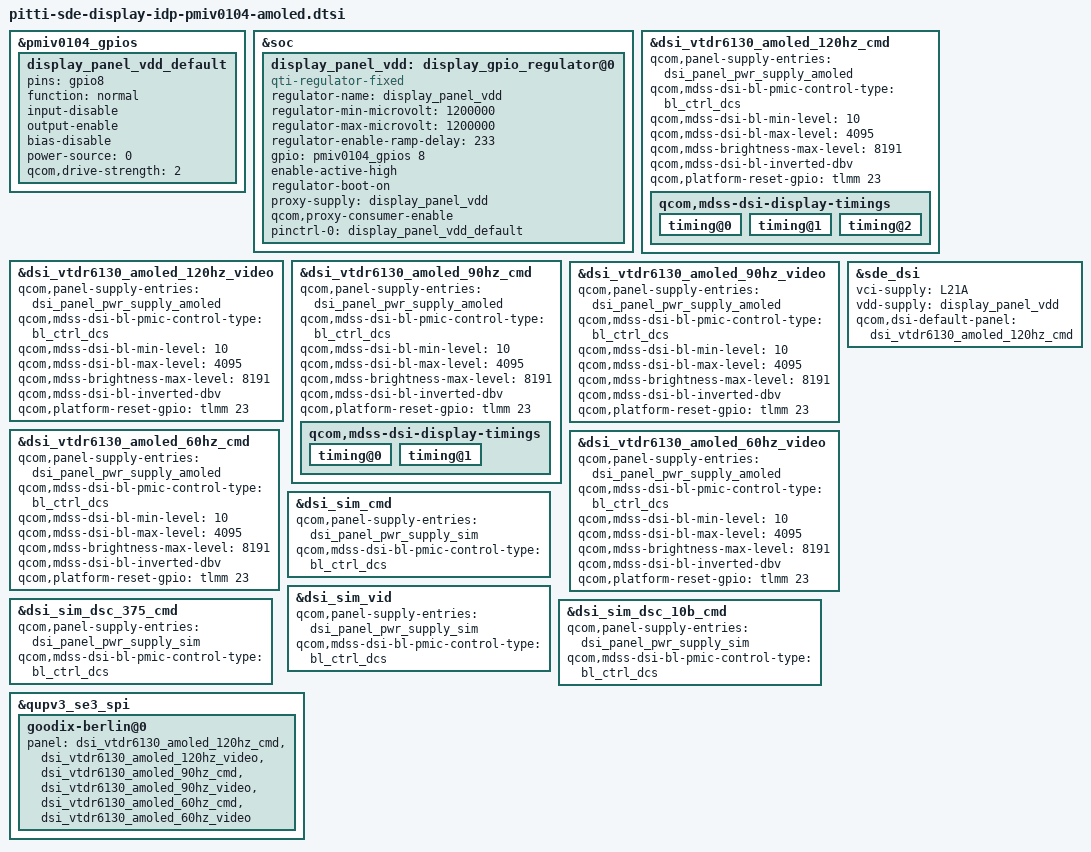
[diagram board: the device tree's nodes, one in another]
#include "pitti-sde-display.dtsi"

&pmiv0104_gpios {
	display_panel_vdd_default: display_panel_vdd_default {
		pins = "gpio8";
		function = "normal";
		input-disable;
		output-enable;
		bias-disable;
		power-source = <0>;
		qcom,drive-strength = <2>;
	};
};

&soc {
	display_panel_vdd: display_gpio_regulator@0 {
		compatible = "qti-regulator-fixed";
		regulator-name = "display_panel_vdd";
		regulator-min-microvolt = <1200000>;
		regulator-max-microvolt = <1200000>;
		regulator-enable-ramp-delay = <233>;
		gpio = <&pmiv0104_gpios 8 0>;
		enable-active-high;
		regulator-boot-on;
		proxy-supply = <&display_panel_vdd>;
		qcom,proxy-consumer-enable;
		pinctrl-names = "default";
		pinctrl-0 = <&display_panel_vdd_default>;
	};
};

&dsi_vtdr6130_amoled_120hz_cmd {
	qcom,panel-supply-entries = <&dsi_panel_pwr_supply_amoled>;
	qcom,mdss-dsi-bl-pmic-control-type = "bl_ctrl_dcs";
	qcom,mdss-dsi-bl-min-level = <10>;
	qcom,mdss-dsi-bl-max-level = <4095>;
	qcom,mdss-brightness-max-level = <8191>;
	qcom,mdss-dsi-bl-inverted-dbv;
	qcom,platform-reset-gpio = <&tlmm 23 0>;
	qcom,mdss-dsi-display-timings {
		timing@0 {
			/delete-property/ qcom,mdss-dsi-panel-clockrate;
		};

		timing@1 {
			/delete-property/ qcom,mdss-dsi-panel-clockrate;
		};

		timing@2 {
			/delete-property/ qcom,mdss-dsi-panel-clockrate;
		};
	};
};

&dsi_vtdr6130_amoled_120hz_video {
	qcom,panel-supply-entries = <&dsi_panel_pwr_supply_amoled>;
	qcom,mdss-dsi-bl-pmic-control-type = "bl_ctrl_dcs";
	qcom,mdss-dsi-bl-min-level = <10>;
	qcom,mdss-dsi-bl-max-level = <4095>;
	qcom,mdss-brightness-max-level = <8191>;
	qcom,mdss-dsi-bl-inverted-dbv;
	qcom,platform-reset-gpio = <&tlmm 23 0>;
};

&dsi_vtdr6130_amoled_90hz_cmd {
	qcom,panel-supply-entries = <&dsi_panel_pwr_supply_amoled>;
	qcom,mdss-dsi-bl-pmic-control-type = "bl_ctrl_dcs";
	qcom,mdss-dsi-bl-min-level = <10>;
	qcom,mdss-dsi-bl-max-level = <4095>;
	qcom,mdss-brightness-max-level = <8191>;
	qcom,mdss-dsi-bl-inverted-dbv;
	qcom,platform-reset-gpio = <&tlmm 23 0>;
	qcom,mdss-dsi-display-timings {
		timing@0 {
			/delete-property/ qcom,mdss-dsi-panel-clockrate;
		};

		timing@1 {
			/delete-property/ qcom,mdss-dsi-panel-clockrate;
		};
	};
};

&dsi_vtdr6130_amoled_90hz_video {
	qcom,panel-supply-entries = <&dsi_panel_pwr_supply_amoled>;
	qcom,mdss-dsi-bl-pmic-control-type = "bl_ctrl_dcs";
	qcom,mdss-dsi-bl-min-level = <10>;
	qcom,mdss-dsi-bl-max-level = <4095>;
	qcom,mdss-brightness-max-level = <8191>;
	qcom,mdss-dsi-bl-inverted-dbv;
	qcom,platform-reset-gpio = <&tlmm 23 0>;
};

&dsi_vtdr6130_amoled_60hz_cmd {
	qcom,panel-supply-entries = <&dsi_panel_pwr_supply_amoled>;
	qcom,mdss-dsi-bl-pmic-control-type = "bl_ctrl_dcs";
	qcom,mdss-dsi-bl-min-level = <10>;
	qcom,mdss-dsi-bl-max-level = <4095>;
	qcom,mdss-brightness-max-level = <8191>;
	qcom,mdss-dsi-bl-inverted-dbv;
	qcom,platform-reset-gpio = <&tlmm 23 0>;
};

&dsi_vtdr6130_amoled_60hz_video {
	qcom,panel-supply-entries = <&dsi_panel_pwr_supply_amoled>;
	qcom,mdss-dsi-bl-pmic-control-type = "bl_ctrl_dcs";
	qcom,mdss-dsi-bl-min-level = <10>;
	qcom,mdss-dsi-bl-max-level = <4095>;
	qcom,mdss-brightness-max-level = <8191>;
	qcom,mdss-dsi-bl-inverted-dbv;
	qcom,platform-reset-gpio = <&tlmm 23 0>;
};

&dsi_sim_cmd {
	qcom,panel-supply-entries = <&dsi_panel_pwr_supply_sim>;
	qcom,mdss-dsi-bl-pmic-control-type = "bl_ctrl_dcs";
};

&dsi_sim_vid {
	qcom,panel-supply-entries = <&dsi_panel_pwr_supply_sim>;
	qcom,mdss-dsi-bl-pmic-control-type = "bl_ctrl_dcs";
};

&dsi_sim_dsc_375_cmd {
	qcom,panel-supply-entries = <&dsi_panel_pwr_supply_sim>;
	qcom,mdss-dsi-bl-pmic-control-type = "bl_ctrl_dcs";
};

&dsi_sim_dsc_10b_cmd {
	qcom,panel-supply-entries = <&dsi_panel_pwr_supply_sim>;
	qcom,mdss-dsi-bl-pmic-control-type = "bl_ctrl_dcs";
};

&sde_dsi {
	vci-supply = <&L21A>;
	vdd-supply = <&display_panel_vdd>;

	qcom,dsi-default-panel = <&dsi_vtdr6130_amoled_120hz_cmd>;
};

&qupv3_se3_spi {
	goodix-berlin@0 {
		panel = <&dsi_vtdr6130_amoled_120hz_cmd
			&dsi_vtdr6130_amoled_120hz_video
			&dsi_vtdr6130_amoled_90hz_cmd
			&dsi_vtdr6130_amoled_90hz_video
			&dsi_vtdr6130_amoled_60hz_cmd
			&dsi_vtdr6130_amoled_60hz_video>;
	};
};
